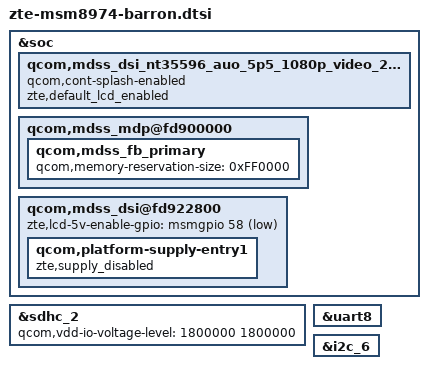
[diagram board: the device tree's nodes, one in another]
/* Copyright (c) 2012-2013, The Linux Foundation. All rights reserved.
 *
 * This program is free software; you can redistribute it and/or modify
 * it under the terms of the GNU General Public License version 2 and
 * only version 2 as published by the Free Software Foundation.
 *
 * This program is distributed in the hope that it will be useful,
 * but WITHOUT ANY WARRANTY; without even the implied warranty of
 * MERCHANTABILITY or FITNESS FOR A PARTICULAR PURPOSE.  See the
 * GNU General Public License for more tadetails.
 */

/include/ "dsi-panel-nt35596-auo-5p5-1080p-video-zte-200.dtsi"
/include/ "touch-key-backlight_barron.dtsi"

/*
 * Added for camera sensor & eeprom by ZTE_JIA_20130828 jia.jia
 */
/include/ "msm8974pro-ab-camera-sensor-mtp-barron.dtsi"
/include/ "msm8974pro-ab-camera-eeprom-mtp-barron.dtsi"

/*bt_dm add for broadcom bt uart & power & sleep */
/include/ "broadcom_4339_bluetooth_uart_power_sleep.dtsi"

/include/ "msm8974-adnc-es325.dtsi"

&soc {	
	qcom,mdss_dsi_nt35596_auo_5p5_1080p_video_200{
		status = "ok";
		qcom,cont-splash-enabled;
		zte,default_lcd_enabled;
	};
		
	qcom,mdss_mdp@fd900000 {
		qcom,mdss_fb_primary {
			qcom,memory-reservation-size = <0xFF0000>;
		};
	};
	
	qcom,mdss_dsi@fd922800 {
		zte,lcd-5v-enable-gpio = <&msmgpio 58 1>;
		qcom,platform-supply-entry1 {
				zte,supply_disabled;
		};
	};
};

&sdhc_2 {
	qcom,vdd-io-voltage-level = <1800000 1800000>;
};

&uart8 {
    status = "ok";
};

&i2c_6 {  /* jht 20130906 add for nxp nfc */
	status = "ok";
};
